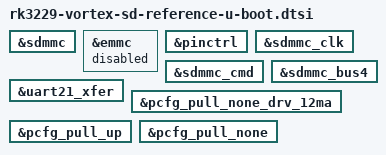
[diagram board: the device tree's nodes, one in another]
// SPDX-License-Identifier: (GPL-2.0+ OR MIT)
#include "rk3229-evb-u-boot.dtsi"

&sdmmc {
    bootph-all;
};

&emmc {
    status = "disabled";
};

&pinctrl { bootph-all; };
&sdmmc_clk { bootph-all; };
&sdmmc_cmd { bootph-all; };
&sdmmc_bus4 { bootph-all; };
&uart21_xfer { bootph-all; };

/* SPL/TPL filtering must retain the config nodes referenced by rockchip,pins. */
&pcfg_pull_none_drv_12ma { bootph-all; };
&pcfg_pull_up { bootph-all; };
&pcfg_pull_none { bootph-all; };
